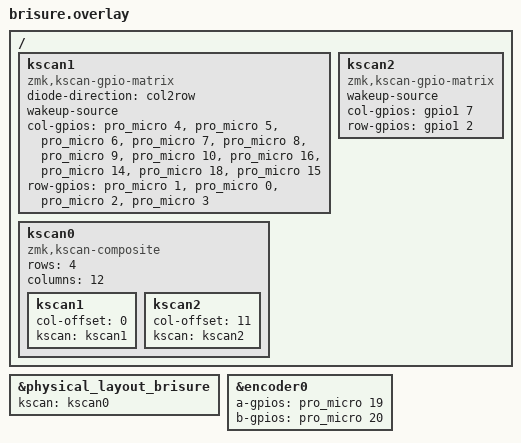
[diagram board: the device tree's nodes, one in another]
#include "brisure.dtsi"

/ {
    kscan1: kscan1 {
        compatible = "zmk,kscan-gpio-matrix";
                diode-direction = "col2row";
        wakeup-source;

        col-gpios
            = <&pro_micro 4 GPIO_ACTIVE_HIGH>
            , <&pro_micro 5 GPIO_ACTIVE_HIGH>
            , <&pro_micro 6 GPIO_ACTIVE_HIGH>
            , <&pro_micro 7 GPIO_ACTIVE_HIGH>
            , <&pro_micro 8 GPIO_ACTIVE_HIGH>
            , <&pro_micro 9 GPIO_ACTIVE_HIGH>
            , <&pro_micro 10 GPIO_ACTIVE_HIGH>
            , <&pro_micro 16 GPIO_ACTIVE_HIGH>
            , <&pro_micro 14 GPIO_ACTIVE_HIGH>
            , <&pro_micro 18 GPIO_ACTIVE_HIGH>
            , <&pro_micro 15 GPIO_ACTIVE_HIGH>
            ;

        row-gpios
            = <&pro_micro 1 (GPIO_ACTIVE_HIGH | GPIO_PULL_DOWN)>
            , <&pro_micro 0 (GPIO_ACTIVE_HIGH | GPIO_PULL_DOWN)>
            , <&pro_micro 2 (GPIO_ACTIVE_HIGH | GPIO_PULL_DOWN)>
            , <&pro_micro 3 (GPIO_ACTIVE_HIGH | GPIO_PULL_DOWN)>
            ;
    };
};

/ {
    kscan2: kscan2 {
        compatible = "zmk,kscan-gpio-matrix";
                wakeup-source;

        col-gpios
            = <&gpio1 7 (GPIO_ACTIVE_HIGH | GPIO_PULL_DOWN)>
            ;

        row-gpios
            = <&gpio1 2 GPIO_OPEN_SOURCE>
            ;
    };
};

/ {
    kscan0: kscan0 {
        compatible = "zmk,kscan-composite";
        rows = <4>;
        columns = <12>;

        kscan1 {
            col-offset = <0>;
            kscan = <&kscan1>;
        };
        kscan2 {
            col-offset = <11>;
            kscan = <&kscan2>;
        };
    };
};

&physical_layout_brisure {
    kscan = <&kscan0>;
};


&encoder0 {
    a-gpios = <&pro_micro 19 (GPIO_ACTIVE_HIGH | GPIO_PULL_UP)>;
    b-gpios = <&pro_micro 20 (GPIO_ACTIVE_HIGH | GPIO_PULL_UP)>;
    status = "okay";
};

